# PIC18F56Q24 register map
Vendor: Microchip
Registers are 8-bit, read-write, reset 0x0 unless marked. A register's access mark holds for its fields unless they carry their own. Addresses are absolute, and some are shared; only a register's first bit layout is shown; [hi:lo] are bit positions; {n}, {i} and the like mark numbered series; 'fields as' and 'values as' point back to an identical list.

## clk_refout
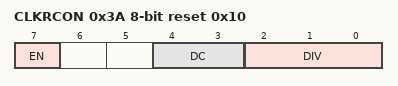
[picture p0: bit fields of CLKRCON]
0x3A CLKRCON reset 0x10
  [7] EN, [4:3] DC, [2:0] DIV
0x3B CLKRCLK
  [3:0] CLK

## lvd_ctrl
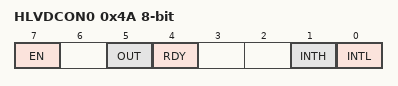
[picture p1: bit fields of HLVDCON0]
0x4A HLVDCON0 reset not defined — (power-on value 0-xx--00)
  [7] EN, [5] OUT ro, [4] RDY ro, [1] INTH, [0] INTL
0x4B HLVDCON1
  [3:0] SEL

## cmp_zxover_ctrl
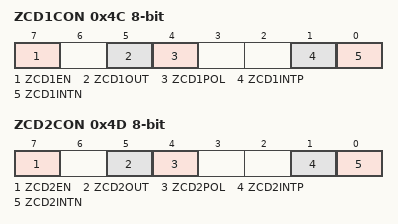
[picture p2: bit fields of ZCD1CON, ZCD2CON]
0x4C ZCD1CON reset not defined — (power-on value 0-x0--00)
  [7] ZCD1EN, [5] ZCD1OUT ro, [4] ZCD1POL, [1] ZCD1INTP, [0] ZCD1INTN
0x4D ZCD2CON reset not defined — (power-on value 0-x0--00)
  [7] ZCD2EN, [5] ZCD2OUT ro, [4] ZCD2POL, [1] ZCD2INTP, [0] ZCD2INTN

## pmd
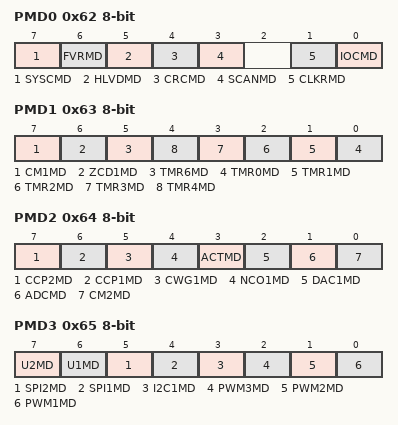
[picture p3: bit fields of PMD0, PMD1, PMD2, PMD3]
0x62 PMD0
  [7] SYSCMD, [6] FVRMD, [5] HLVDMD, [4] CRCMD, [3] SCANMD, [1] CLKRMD, [0] IOCMD
0x63 PMD1
  [7] CM1MD, [6] ZCD1MD, [5] TMR6MD, [n] TMR{n}MD (n=0..4)
0x64 PMD2
  [7] CCP2MD, [6] CCP1MD, [5] CWG1MD, [4] NCO1MD, [3] ACTMD, [2] DAC1MD, [1] ADCMD, [0] CM2MD
0x65 PMD3
  [7] U2MD, [6] U1MD, [5] SPI2MD, [4] SPI1MD, [3] I2C1MD, [2] PWM3MD, [1] PWM2MD, [0] PWM1MD
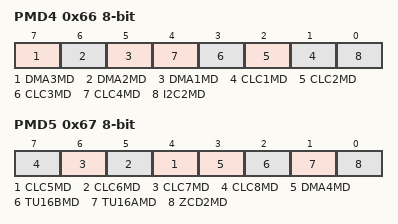
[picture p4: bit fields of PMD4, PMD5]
0x66 PMD4
  [7] DMA3MD, [6] DMA2MD, [5] DMA1MD, [n] CLC{n}MD (n=1..4), [0] I2C2MD
0x67 PMD5
  [n-1] CLC{n}MD (n=5..8), [3] DMA4MD, [2] TU16BMD, [1] TU16AMD, [0] ZCD2MD
0x68 PMD6
  [0] PORTWMD

## cmp_rr_ctrl
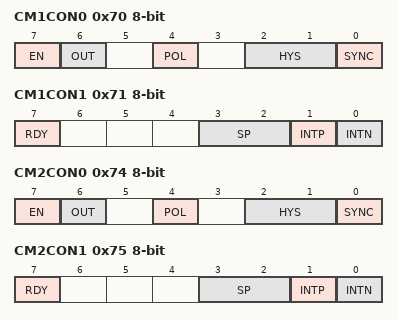
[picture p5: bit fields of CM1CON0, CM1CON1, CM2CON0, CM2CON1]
0x70 CM1CON0 reset not defined — COMPARATOR CONTROL REGISTER 0 (power-on value 00-0-xx0)
  [7] EN — Comparator Enable bit
  [6] OUT ro — Comparator Output bit
  [4] POL — Comparator Output Polarity Select bit
  [2:1] HYS — Comparator Hysteresis Enable bit
  [0] SYNC — Comparator Output Synchronous Mode bit
0x71 CM1CON1 reset not defined — COMPARATOR CONTROL REGISTER 1 (power-on value x---xx00)
  [7] RDY
  [3:2] SP
  [1] INTP — Comparator Interrupt on Positive going edge Enable bits
  [0] INTN — Comparator Interrupt on Negative going edge Enable bits
0x72 CM1NCH — COMPARATOR INVERTING CHANNEL SELECT REGISTER
  [2:0] NCH — Comparator Inverting Input Channel Select bits
0x73 CM1PCH — COMPARATOR NON-INVERTING CHANNEL SELECT REGISTER
  [2:0] PCH — Comparator Non-Inverting Input Channel Select bits
0x74 CM2CON0 reset not defined — COMPARATOR CONTROL REGISTER 0 (power-on value 00-0-xx0)
  fields as CM1CON0
0x75 CM2CON1 reset not defined — COMPARATOR CONTROL REGISTER 1 (power-on value x---xx00)
  fields as CM1CON1
0x76 CM2NCH — COMPARATOR INVERTING CHANNEL SELECT REGISTER
  [2:0] NCH — Comparator Inverting Input Channel Select bits
0x77 CM2PCH — COMPARATOR NON-INVERTING CHANNEL SELECT REGISTER
  [2:0] PCH — Comparator Non-Inverting Input Channel Select bits

## wdt_windowed
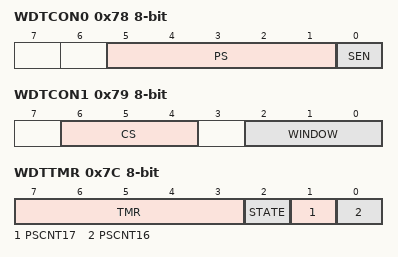
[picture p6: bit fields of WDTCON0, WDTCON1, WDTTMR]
0x78 WDTCON0 reset not defined — (power-on value --qqqqq0)
  [5:1] PS, [0] SEN
0x79 WDTCON1 reset not defined — (power-on value -qqq-qqq)
  [6:4] CS, [2:0] WINDOW
0x7A WDTPSL ro
  [7:0] PSCNTL
0x7B WDTPSH ro
  [7:0] PSCNTH
0x7C WDTTMR ro
  [7:3] TMR, [2] STATE, [1] PSCNT17, [0] PSCNT16

## dac_nbit_ctrl
0x7D DAC1DATL
  [7:0] DAC1R
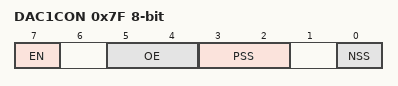
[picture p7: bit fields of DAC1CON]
0x7F DAC1CON
  [7] EN, [5:4] OE, [3:2] PSS, [0] NSS

## spi
0x80 SPI1RXB ro reset not defined — (power-on value xxxxxxxx)
  [7:0] RXB
0x81 SPI1TXB wo reset not defined — (power-on value xxxxxxxx)
  [7:0] TXB
0x82 SPI1TCNTL
  [7:0] TCNTL
0x83 SPI1TCNTH
  [2:0] TCNTH
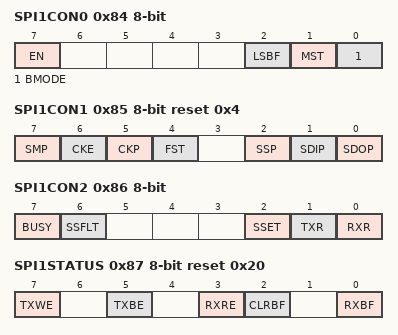
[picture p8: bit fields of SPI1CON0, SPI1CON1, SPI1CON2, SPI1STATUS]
0x84 SPI1CON0
  [7] EN, [2] LSBF, [1] MST, [0] BMODE
0x85 SPI1CON1 reset 0x4
  [7] SMP, [6] CKE, [5] CKP, [4] FST, [2] SSP, [1] SDIP, [0] SDOP
0x86 SPI1CON2
  [7] BUSY ro, [6] SSFLT ro, [2] SSET, [1] TXR, [0] RXR
0x87 SPI1STATUS reset 0x20
  [7] TXWE — (can only be cleared)
  [5] TXBE ro
  [3] RXRE — (can only be cleared)
  [2] CLRBF — (can only be set)
  [0] RXBF ro
0x88 SPI1TWIDTH
  [2:0] TWIDTH
0x89 SPI1BAUD
  [7:0] BAUD
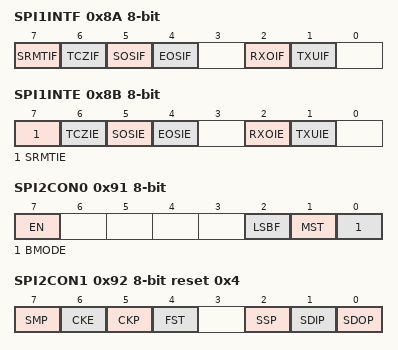
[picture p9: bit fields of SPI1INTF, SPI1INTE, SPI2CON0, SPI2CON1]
0x8A SPI1INTF
  [7] SRMTIF, [6] TCZIF, [5] SOSIF, [4] EOSIF, [2] RXOIF, [1] TXUIF
0x8B SPI1INTE
  [7] SRMTIE, [6] TCZIE, [5] SOSIE, [4] EOSIE, [2] RXOIE, [1] TXUIE
0x8C SPI1CLK
  [4:0] CLKSEL
0x8D SPI2RXB ro reset not defined — (power-on value xxxxxxxx)
  [7:0] RXB
0x8E SPI2TXB wo reset not defined — (power-on value xxxxxxxx)
  [7:0] TXB
0x8F SPI2TCNTL
  [7:0] TCNTL
0x90 SPI2TCNTH
  [2:0] TCNTH
0x91 SPI2CON0
  [7] EN, [2] LSBF, [1] MST, [0] BMODE
0x92 SPI2CON1 reset 0x4
  [7] SMP, [6] CKE, [5] CKP, [4] FST, [2] SSP, [1] SDIP, [0] SDOP
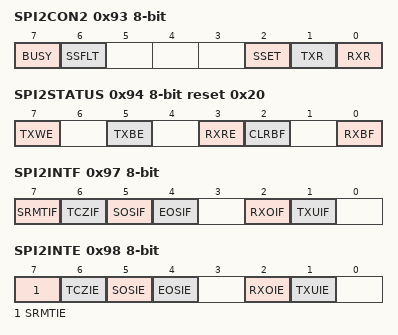
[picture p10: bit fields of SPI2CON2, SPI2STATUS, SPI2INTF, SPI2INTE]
0x93 SPI2CON2
  [7] BUSY ro, [6] SSFLT ro, [2] SSET, [1] TXR, [0] RXR
0x94 SPI2STATUS reset 0x20
  fields as SPI1STATUS
0x95 SPI2TWIDTH
  [2:0] TWIDTH
0x96 SPI2BAUD
  [7:0] BAUD
0x97 SPI2INTF
  [7] SRMTIF, [6] TCZIF, [5] SOSIF, [4] EOSIF, [2] RXOIF, [1] TXUIF
0x98 SPI2INTE
  [7] SRMTIE, [6] TCZIE, [5] SOSIE, [4] EOSIE, [2] RXOIE, [1] TXUIE
0x99 SPI2CLK
  [4:0] CLKSEL
